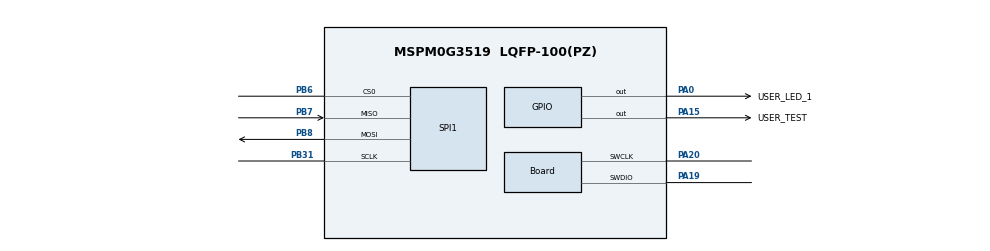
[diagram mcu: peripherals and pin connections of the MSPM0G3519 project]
//@cliArgs --device "MSPM0G351X" --package "LQFP-100(PZ)" --part "Default"
//@v2CliArgs --device "MSPM0G3519" --package "LQFP-100(PZ)"
// @cliArgs --board /ti/boards/LP_MSPM0G3519 --rtos nortos

/**
 * Import the modules used in this configuration.
 */
const GPIO   = scripting.addModule("/ti/driverlib/GPIO", {}, false);
const GPIO1  = GPIO.addInstance();
const SPI    = scripting.addModule("/ti/driverlib/SPI", {}, false);
const SPI1   = SPI.addInstance();
const SYSCTL = scripting.addModule("/ti/driverlib/SYSCTL");

/**
 * Write custom configuration values to the imported modules.
 */
GPIO1.$name                          = "GPIO_LEDS";
GPIO1.associatedPins.create(2);
GPIO1.associatedPins[0].$name        = "USER_LED_1";
GPIO1.associatedPins[0].initialValue = "SET";
GPIO1.associatedPins[0].pin.$assign  = "PA0";
GPIO1.associatedPins[1].$name        = "USER_TEST";
GPIO1.associatedPins[1].initialValue = "SET";
GPIO1.associatedPins[1].pin.$assign  = "PA15";

const Board                       = scripting.addModule("/ti/driverlib/Board", {}, false);
Board.peripheral.$assign          = "DEBUGSS";
Board.peripheral.swclkPin.$assign = "PA20";
Board.peripheral.swdioPin.$assign = "PA19";

SPI1.$name                      = "SPI_0";
SPI1.targetBitRate              = 100000;
SPI1.enabledInterrupts          = ["RX"];
SPI1.rxFifoThreshold            = "DL_SPI_RX_FIFO_LEVEL_ONE_FRAME";
SPI1.txFifoThreshold            = "DL_SPI_TX_FIFO_LEVEL_EMPTY";
SPI1.peripheral.$assign         = "SPI1";
SPI1.peripheral.sclkPin.$assign = "PB31";
SPI1.peripheral.mosiPin.$assign = "PB8";
SPI1.peripheral.misoPin.$assign = "PB7";
SPI1.peripheral.cs0Pin.$assign  = "PB6";

SYSCTL.forceDefaultClkConfig = true;
SYSCTL.clockTreeEn           = true;

const ProjectConfig              = scripting.addModule("/ti/project_config/ProjectConfig", {}, false);
ProjectConfig.migrationCondition = true;
